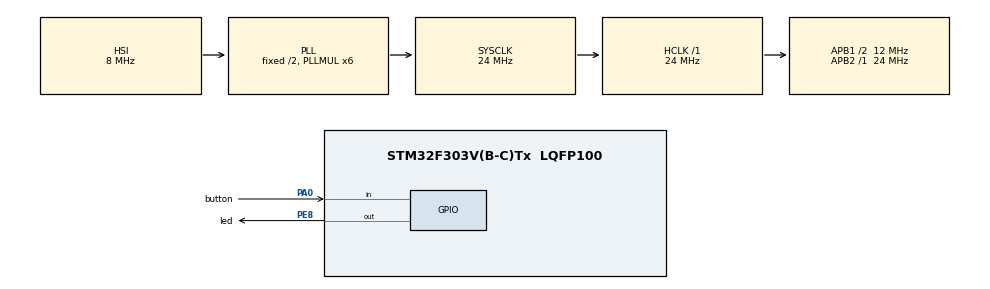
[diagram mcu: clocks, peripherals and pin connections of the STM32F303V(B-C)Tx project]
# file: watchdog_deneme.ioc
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IWDG.Prescaler=IWDG_PRESCALER_32
IWDG.Reload=2500
Mcu.Family=STM32F3
Mcu.Name=STM32F303V(B-C)Tx
Mcu.Package=LQFP100
NVIC.PriorityGroup=NVIC_PRIORITYGROUP_0
PA0.GPIO_Label=button
PA0.Signal=GPIO_Input
PA13.Mode=Serial_Wire
PA13.Signal=SYS_JTMS-SWDIO
PA14.Mode=Serial_Wire
PA14.Signal=SYS_JTCK-SWCLK
PE8.GPIO_Label=led
PE8.Signal=GPIO_Output
ProjectManager.HeapSize=0x200
ProjectManager.StackSize=0x400
ProjectManager.TargetToolchain=STM32CubeIDE
RCC.AHBFreq_Value=24000000
RCC.APB1CLKDivider=RCC_HCLK_DIV2
RCC.APB1Freq_Value=12000000
RCC.APB1TimFreq_Value=24000000
RCC.APB2Freq_Value=24000000
RCC.APB2TimFreq_Value=24000000
RCC.CortexFreq_Value=24000000
RCC.HCLKFreq_Value=24000000
RCC.HSE_VALUE=8000000
RCC.HSI_VALUE=8000000
RCC.LSE_VALUE=32768
RCC.PLLMUL=RCC_PLL_MUL6
RCC.SYSCLKFreq_VALUE=24000000
RCC.SYSCLKSourceVirtual=RCC_SYSCLKSOURCE_PLLCLK
RCC.USBFreq_Value=24000000
VP_IWDG_VS_IWDG.Mode=IWDG_Activate
board=STM32F3DISCOVERY

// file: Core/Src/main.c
/* USER CODE BEGIN Header */
/**
  ******************************************************************************
  * @file           : main.c
  * @brief          : Main program body
  ******************************************************************************
  * @attention
  *
  * Copyright (c) 2026 STMicroelectronics.
  * All rights reserved.
  *
  * This software is licensed under terms that can be found in the LICENSE file
  * in the root directory of this software component.
  * If no LICENSE file comes with this software, it is provided AS-IS.
  *
  ******************************************************************************
  */
/* USER CODE END Header */
#include "main.h"
#include "stm32f3xx_hal.h"

/* USER CODE BEGIN PTD */
enum butondurum{
	butona_basidimi,
	ne_kadar_basildi,
	dongu
};

enum butondurum ilk = butona_basidimi;
/* USER CODE END PTD */

IWDG_HandleTypeDef hiwdg;

/* USER CODE BEGIN PV */
volatile int buton = 0;
/* USER CODE END PV */

void SystemClock_Config(void);
static void MX_GPIO_Init(void);
static void MX_IWDG_Init(void);

int main(void)
{

  /* MCU Configuration--------------------------------------------------------*/

  /* Reset of all peripherals, Initializes the Flash interface and the Systick. */
  HAL_Init();

  /* Configure the system clock */
  SystemClock_Config();

  /* Initialize all configured peripherals */
  MX_GPIO_Init();
  MX_IWDG_Init();
  /* USER CODE BEGIN 2 */
for(int i = 0; i<5; i++){
	HAL_GPIO_TogglePin(GPIOE, GPIO_PIN_8);
	HAL_Delay(100);
}
uint32_t laveraj = 500;
uint32_t lson = HAL_GetTick();
uint32_t bson = 50;
uint32_t bsaniye = HAL_GetTick();
//GPIO_PinState buttonState = GPIO_PIN_RESET;
//GPIO_PinState lastFlickerableState = GPIO_PIN_RESET;
  /* USER CODE END 2 */

  /* Infinite loop */
  while (1)
  {
	  //uint32_t banliksan = HAL_GetTick();
	  uint32_t anliksan = HAL_GetTick();
if(anliksan - lson >= laveraj){
	HAL_GPIO_TogglePin(GPIOE, GPIO_PIN_8);
	lson = anliksan;
}
HAL_IWDG_Refresh(&hiwdg);

switch(ilk){

case butona_basidimi:
	if(HAL_GPIO_ReadPin(GPIOA, GPIO_PIN_0) == GPIO_PIN_SET){
		bsaniye = anliksan;
		ilk = ne_kadar_basildi;
	}
	break;

case ne_kadar_basildi:
	if(anliksan - bsaniye >= bson){
		if(HAL_GPIO_ReadPin(GPIOA, GPIO_PIN_0) == GPIO_PIN_SET){

			ilk = dongu;
		}else{
			ilk = butona_basidimi;
		}
	}
	break;

case dongu:
	while(1){}

	break;

}

  }
}

void SystemClock_Config(void)
{
  RCC_OscInitTypeDef RCC_OscInitStruct = {0};
  RCC_ClkInitTypeDef RCC_ClkInitStruct = {0};

  /** Initializes the RCC Oscillators according to the specified parameters
  * in the RCC_OscInitTypeDef structure.
  */
  RCC_OscInitStruct.OscillatorType = RCC_OSCILLATORTYPE_HSI|RCC_OSCILLATORTYPE_LSI;
  RCC_OscInitStruct.HSIState = RCC_HSI_ON;
  RCC_OscInitStruct.HSICalibrationValue = RCC_HSICALIBRATION_DEFAULT;
  RCC_OscInitStruct.LSIState = RCC_LSI_ON;
  RCC_OscInitStruct.PLL.PLLState = RCC_PLL_ON;
  RCC_OscInitStruct.PLL.PLLSource = RCC_PLLSOURCE_HSI;
  RCC_OscInitStruct.PLL.PLLMUL = RCC_PLL_MUL6;
  if (HAL_RCC_OscConfig(&RCC_OscInitStruct) != HAL_OK)
  {
    Error_Handler();
  }

  /** Initializes the CPU, AHB and APB buses clocks
  */
  RCC_ClkInitStruct.ClockType = RCC_CLOCKTYPE_HCLK|RCC_CLOCKTYPE_SYSCLK
                              |RCC_CLOCKTYPE_PCLK1|RCC_CLOCKTYPE_PCLK2;
  RCC_ClkInitStruct.SYSCLKSource = RCC_SYSCLKSOURCE_PLLCLK;
  RCC_ClkInitStruct.AHBCLKDivider = RCC_SYSCLK_DIV1;
  RCC_ClkInitStruct.APB1CLKDivider = RCC_HCLK_DIV2;
  RCC_ClkInitStruct.APB2CLKDivider = RCC_HCLK_DIV1;

  if (HAL_RCC_ClockConfig(&RCC_ClkInitStruct, FLASH_LATENCY_0) != HAL_OK)
  {
    Error_Handler();
  }
}

static void MX_IWDG_Init(void)
{

  hiwdg.Instance = IWDG;
  hiwdg.Init.Prescaler = IWDG_PRESCALER_32;
  hiwdg.Init.Window = 4095;
  hiwdg.Init.Reload = 2500;
  if (HAL_IWDG_Init(&hiwdg) != HAL_OK)
  {
    Error_Handler();
  }

}

static void MX_GPIO_Init(void)
{
  GPIO_InitTypeDef GPIO_InitStruct = {0};

  /* GPIO Ports Clock Enable */
  __HAL_RCC_GPIOA_CLK_ENABLE();
  __HAL_RCC_GPIOE_CLK_ENABLE();

  /*Configure GPIO pin Output Level */
  HAL_GPIO_WritePin(led_GPIO_Port, led_Pin, GPIO_PIN_RESET);

  /*Configure GPIO pin : button_Pin */
  GPIO_InitStruct.Pin = button_Pin;
  GPIO_InitStruct.Mode = GPIO_MODE_INPUT;
  GPIO_InitStruct.Pull = GPIO_NOPULL;
  HAL_GPIO_Init(button_GPIO_Port, &GPIO_InitStruct);

  /*Configure GPIO pin : led_Pin */
  GPIO_InitStruct.Pin = led_Pin;
  GPIO_InitStruct.Mode = GPIO_MODE_OUTPUT_PP;
  GPIO_InitStruct.Pull = GPIO_NOPULL;
  GPIO_InitStruct.Speed = GPIO_SPEED_FREQ_LOW;
  HAL_GPIO_Init(led_GPIO_Port, &GPIO_InitStruct);

}

void Error_Handler(void)
{
  __disable_irq();
  while (1)
  {
  }
}
